# PIC32CX2051BZ62132 device description
Architecture: CORTEX-M4; Family: PIC32CX; Series: PIC32CXBZ62
Registers are 32-bit, read-write, reset 0x0 unless marked. A register's access mark holds for its fields unless they carry their own. Offsets are from the block's base; [hi:lo] are bit positions; lines under a group give offsets from that group; {n}, {i} and the like mark numbered series.

## EFUSE — Efuse Memory Map
Instances: EFUSE 0x0 in fuses
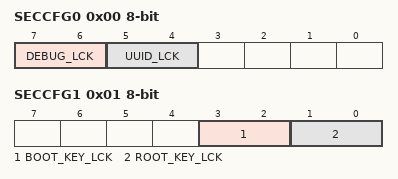
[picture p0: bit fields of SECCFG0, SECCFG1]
0x00 SECCFG0 8-bit — Secure Configuration
  [7:6] DEBUG_LCK — Lock bits for debug/programming
    0=Debug is not locked; 1=Debug is locked; 2=Debug is locked; 3=Debug is locked
  [5:4] UUID_LCK — Programming lock bits for Unique ID fuses
    0=Unique ID is not locked; 1=Unique ID is locked and cannot be programmed; 2=Unique ID is locked and cannot be programmed; 3=Unique ID is locked and cannot be programmed
0x01 SECCFG1 8-bit — Secure Configuration
  [3:2] BOOT_KEY_LCK — Lock bits for Secure Boot/OTA Key
    0=Secure boot key is not locked; 1=Secure boot key is locked and cannot be programmed; 2=Secure boot key is locked and cannot be programmed; 3=Secure boot key is locked and cannot be programmed
  [1:0] ROOT_KEY_LCK — Lock bits for storage root Key
    0=Storage root key is not locked; 1=Storage root key is locked and cannot be programmed; 2=Storage root key is locked and cannot be programmed; 3=Storage root key is locked and cannot be programmed
0x02 SECCFG2 8-bit — Secure Configuration
  [0] ADD_BOOT_KEY — Additional boot Key bit
{0x4+i} ANTIROLLBACKCOUNTER[{i}] (i=0..31) 8-bit
  [7:0] ANTIROLLBACKCOUNTER — Anti rollback counter bits
{0x24+i} LIFECYCLECOUNTER[{i}] (i=0..1) 8-bit
  [7:0] LIFECYCLECOUNTER — Life cycle counter bits
{0x26+i} SECUREBOOTKEY[{i}] (i=0..47) 8-bit
  [7:0] SECUREBOOTKEY — Secure boot key bits
{0x1D8+i} UUID[{i}] (i=0..15) 8-bit — Unique ID
  [7:0] UUID — Unique ID bits

## EVSYS — Event System Interface
Instances: EVSYS 0x41006000
0x00 CTRLA 8-bit — Control
  [0] SWRST — Software Reset
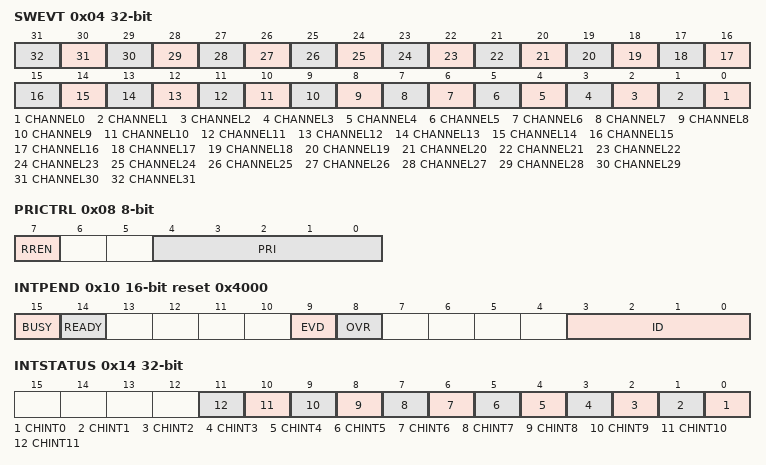
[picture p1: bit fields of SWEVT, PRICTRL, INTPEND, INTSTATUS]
0x04 SWEVT wo — Software Event
  [n] CHANNEL{n} (n=0..31) — Channel {n} Software Selection
0x08 PRICTRL 8-bit — Priority Control
  [7] RREN — Round-Robin Scheduling Enable
  [4:0] PRI — Channel Priority Number
0x10 INTPEND 16-bit reset 0x4000 — Channel Pending Interrupt
  [15] BUSY
  [14] READY
  [9] EVD — Channel Event Detected
  [8] OVR — Channel Overrun
  [3:0] ID — Channel ID
0x14 INTSTATUS ro — Interrupt Status
  [n] CHINT{n} (n=0..11) — Channel {n} Pending Interrupt
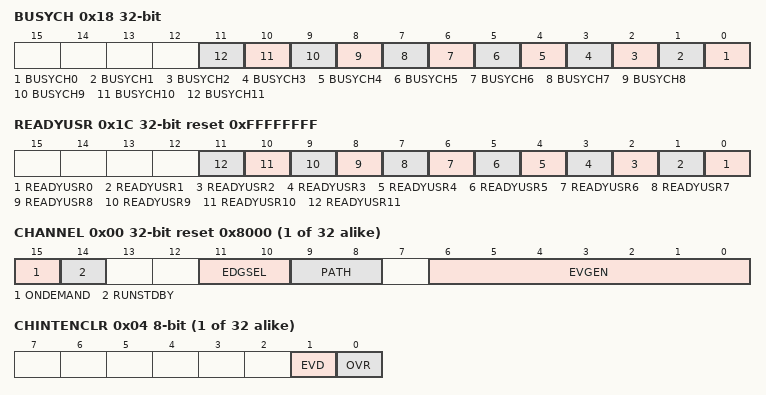
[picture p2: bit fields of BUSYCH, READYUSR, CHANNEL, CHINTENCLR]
0x18 BUSYCH ro — Busy Channels
  [n] BUSYCH{n} (n=0..11) — Busy Channel {n}
0x1C READYUSR ro reset 0xFFFFFFFF — Ready Users
  [n] READYUSR{n} (n=0..11) — Ready User for Channel {n}
{0x20+8i} CHANNEL[{i}] (i=0..31) group
  0x00 CHANNEL reset 0x8000 — Channel n Control
    [15] ONDEMAND — Generic Clock On Demand
    [14] RUNSTDBY — Run in standby
    [11:10] EDGSEL — Edge Detection Selection
      0=NO_EVT_OUTPUT (No event output when using the resynchronized or synchronous path); 1=RISING_EDGE (Event detection only on the rising edge of the signal from the event generator when using the resynchronized or synchronous path); 2=FALLING_EDGE (Event detection only on the falling edge of the signal from the event generator when using the resynchronized or synchronous path); 3=BOTH_EDGES (Event detection on rising and falling edges of the signal from the event generator when using the resynchronized or synchronous path)
    [9:8] PATH — Path Selection
      0=SYNCHRONOUS (Synchronous path); 1=RESYNCHRONIZED (Resynchronized path); 2=ASYNCHRONOUS (Asynchronous path)
    [6:0] EVGEN — Event Generator Selection
  0x04 CHINTENCLR 8-bit (atomic clear) — Channel n Interrupt Enable Clear
    [1] EVD — Channel Event Detected Interrupt Disable
    [0] OVR — Channel Overrun Interrupt Disable
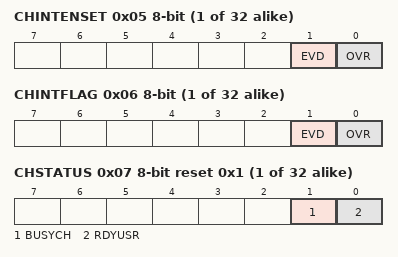
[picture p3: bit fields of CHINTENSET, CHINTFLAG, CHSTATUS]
  0x05 CHINTENSET 8-bit (atomic set) — Channel n Interrupt Enable Set
    [1] EVD — Channel Event Detected Interrupt Enable
    [0] OVR — Channel Overrun Interrupt Enable
  0x06 CHINTFLAG 8-bit (atomic clear) — Channel n Interrupt Flag Status and Clear
    [1] EVD — Channel Event Detected
    [0] OVR — Channel Overrun
  0x07 CHSTATUS 8-bit ro reset 0x1 — Channel n Status
    [1] BUSYCH — Busy Channel
    [0] RDYUSR — Ready User
{0x120+4i} USER[{i}] (i=0..58) — User Multiplexer n
  [5:0] CHANNEL — Channel Event Selection
